# ATSAMR30E18A device description
Architecture: CORTEX-M0PLUS; Family: SAMR; Series: SAMR30
Registers are 32-bit, read-write, reset 0x0 unless marked. A register's access mark holds for its fields unless they carry their own. Offsets are from the block's base; [hi:lo] are bit positions; lines under a group give offsets from that group; {n}, {i} and the like mark numbered series; 'fields as' and 'values as' point back to an identical list; <NAME> marks a mode.

## PORT — Port Module
Instances: PORT 0x40002800, PORT_IOBUS 0x60000000
{0x0+0x80*i} GROUP[{i}] (i=0..2) group
  0x00 DIR — Data Direction
    [31:0] DIR — Port Data Direction
  0x04 DIRCLR (atomic clear of DIR) — Data Direction Clear
    [31:0] DIRCLR — Port Data Direction Clear
  0x08 DIRSET (atomic set of DIR) — Data Direction Set
    [31:0] DIRSET — Port Data Direction Set
  0x0C DIRTGL (atomic toggle of DIR) — Data Direction Toggle
    [31:0] DIRTGL — Port Data Direction Toggle
  0x10 OUT — Data Output Value
    [31:0] OUT — Port Data Output Value
  0x14 OUTCLR (atomic clear of OUT) — Data Output Value Clear
    [31:0] OUTCLR — Port Data Output Value Clear
  0x18 OUTSET (atomic set of OUT) — Data Output Value Set
    [31:0] OUTSET — Port Data Output Value Set
  0x1C OUTTGL (atomic toggle of OUT) — Data Output Value Toggle
    [31:0] OUTTGL — Port Data Output Value Toggle
  0x20 IN ro — Data Input Value
    [31:0] IN — Port Data Input Value
  0x24 CTRL — Control
    [31:0] SAMPLING — Input Sampling Mode
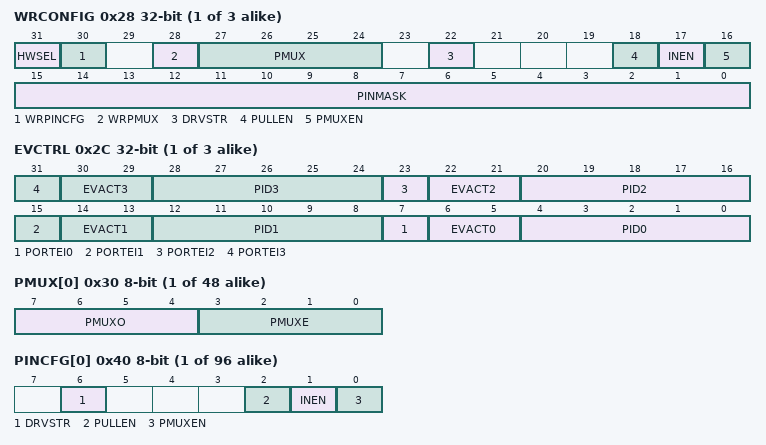
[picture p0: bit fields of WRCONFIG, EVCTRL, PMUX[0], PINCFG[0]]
  0x28 WRCONFIG wo — Write Configuration
    [31] HWSEL — Half-Word Select
    [30] WRPINCFG — Write PINCFG Registers
    [28] WRPMUX — Write PMUX Registers
    [27:24] PMUX — Peripheral Multiplexing Template
    [22] DRVSTR — Output Driver Strength Selection
    [18] PULLEN — Pull Enable
    [17] INEN — Input Enable
    [16] PMUXEN — Select Peripheral Multiplexer
    [15:0] PINMASK — Pin Mask for Multiple Pin Configuration
  0x2C EVCTRL — Event Input Control
    [8n+7] PORTEI{n} (n=0..3) — Port Event Enable Input {n}
    [8n+6:8n+5] EVACT{n} (n=0..3) — Port Event Action {n}
    [8n+4:8n] PID{n} (n=0..3) — Port Event Pin Identifier {n}
  {0x30+j} PMUX[{j}] (j=0..15) 8-bit — Peripheral Multiplexing n
    [7:4] PMUXO — Peripheral Multiplexing for Odd-Numbered Pin
    [3:0] PMUXE — Peripheral Multiplexing for Even-Numbered Pin
  {0x40+j} PINCFG[{j}] (j=0..31) 8-bit — Pin Configuration n
    [6] DRVSTR — Output Driver Strength Selection
    [2] PULLEN — Pull Enable
    [1] INEN — Input Enable
    [0] PMUXEN — Select Peripheral Multiplexer

## RFCTRL — RF212B control module
Instances: RFCTRL 0x42003C00
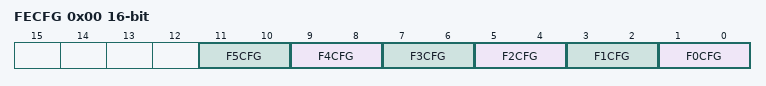
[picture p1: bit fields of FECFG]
0x00 FECFG 16-bit — Front-end control bus configuration
  [2n+1:2n] F{n}CFG (n=0..5) — Front-end control signal {n} configuration

## RSTC — Reset Controller
Instances: RSTC 0x40000800
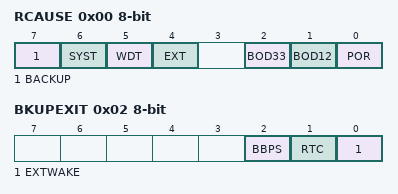
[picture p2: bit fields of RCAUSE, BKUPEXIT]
0x00 RCAUSE 8-bit ro reset not defined — Reset Cause
  [7] BACKUP — Backup Reset
  [6] SYST — System Reset Request
  [5] WDT — Watchdog Reset
  [4] EXT — External Reset
  [2] BOD33 — Brown Out 33 Detector Reset
  [1] BOD12 — Brown Out 12 Detector Reset
  [0] POR — Power On Reset
0x02 BKUPEXIT 8-bit ro reset not defined — Backup Exit Source
  [2] BBPS — Battery Backup Power Switch
  [1] RTC — Real Timer Counter Interrupt
  [0] EXTWAKE — External Wakeup
0x04 WKDBCONF 8-bit — Wakeup Debounce Configuration
  [4:0] WKDBCNT — Wakeup Debounce Counter
    0=OFF (No debouncing.Input pin is low or high level sensitive depending on its WKPOLx bit.); 1=2CK32 (Input pin shall be active for at least two 32kHz clock period.); 2=3CK32 (Input pin shall be active for at least three 32kHz clock period.); 3=32CK32 (Input pin shall be active for at least 32 32kHz clock period.); 4=512CK32 (Input pin shall be active for at least 512 32kHz clock period.); 5=4096CK32 (Input pin shall be active for at least 4096 32kHz clock period.); 6=32768CK32 (Input pin shall be active for at least 32768 32kHz clock period.)
0x08 WKPOL 16-bit — Wakeup Polarity
  [7:0] WKPOL
0x0C WKEN 16-bit — Wakeup Enable
  [7:0] WKEN
0x10 WKCAUSE 16-bit — Wakeup Cause

## USB_DESCRIPTOR — Universal Serial Bus
Modes: DEVICE when USB.CTRLA.MODE=0 (USB is Device); HOST when USB.CTRLA.MODE=1 (USB is Host)
{0x0+0x10*i} DEVICE_DESC_BANK[{i}] (i=0..1) <DEVICE> group
  0x00 ADDR <DEVICE> reset not defined — DEVICE_DESC_BANK Endpoint Bank, Adress of Data Buffer
    [31:0] ADDR — Adress of data buffer
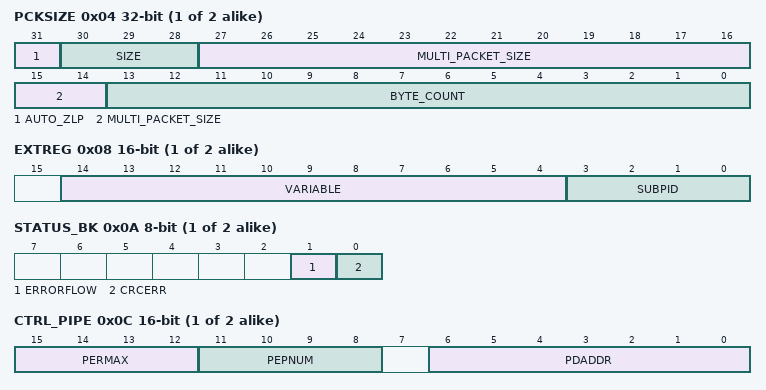
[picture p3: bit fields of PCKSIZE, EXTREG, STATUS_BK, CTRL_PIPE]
  0x04 PCKSIZE <DEVICE> reset not defined — DEVICE_DESC_BANK Endpoint Bank, Packet Size
    [31] AUTO_ZLP — Automatic Zero Length Packet
    [30:28] SIZE — Enpoint size
    [27:14] MULTI_PACKET_SIZE — Multi Packet In or Out size
    [13:0] BYTE_COUNT
  0x08 EXTREG <DEVICE> 16-bit reset not defined — DEVICE_DESC_BANK Endpoint Bank, Extended
    [14:4] VARIABLE — Variable field send with extended token
    [3:0] SUBPID — SUBPID field send with extended token
  0x0A STATUS_BK <DEVICE> 8-bit reset not defined — DEVICE_DESC_BANK Enpoint Bank, Status of Bank
    [1] ERRORFLOW — Error Flow Status
    [0] CRCERR — CRC Error Status
{0x0+0x10*i} HOST_DESC_BANK[{i}] (i=0..1) <HOST> group
  0x00 ADDR <HOST> reset not defined — HOST_DESC_BANK Host Bank, Adress of Data Buffer
    [31:0] ADDR — Adress of data buffer
  0x04 PCKSIZE <HOST> reset not defined — HOST_DESC_BANK Host Bank, Packet Size
    [31] AUTO_ZLP — Automatic Zero Length Packet
    [30:28] SIZE — Pipe size
    [27:14] MULTI_PACKET_SIZE — Multi Packet In or Out size
    [13:0] BYTE_COUNT
  0x08 EXTREG <HOST> 16-bit reset not defined — HOST_DESC_BANK Host Bank, Extended
    fields as DEVICE_DESC_BANK[0]<DEVICE>.EXTREG<DEVICE>
  0x0A STATUS_BK <HOST> 8-bit reset not defined — HOST_DESC_BANK Host Bank, Status of Bank
    [1] ERRORFLOW — Error Flow Status
    [0] CRCERR — CRC Error Status
  0x0C CTRL_PIPE <HOST> 16-bit — HOST_DESC_BANK Host Bank, Host Control Pipe
    [15:12] PERMAX — Pipe Error Max Number
    [11:8] PEPNUM — Pipe Endpoint Number
    [6:0] PDADDR — Pipe Device Adress
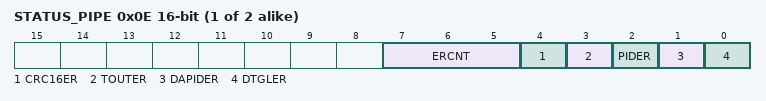
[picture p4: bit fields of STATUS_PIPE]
  0x0E STATUS_PIPE <HOST> 16-bit reset not defined — HOST_DESC_BANK Host Bank, Host Status Pipe
    [7:5] ERCNT — Pipe Error Count
    [4] CRC16ER — CRC16 Error
    [3] TOUTER — Time Out Error
    [2] PIDER — PID Error
    [1] DAPIDER — Data PID Error
    [0] DTGLER — Data Toggle Error

## Notices in the file
Copyright (c) 2018 Microchip Technology Inc.
SPDX-License-Identifier: Apache-2.0
Licensed under the Apache License, Version 2.0 (the "License");
you may not use this file except in compliance with the License.
You may obtain a copy of the License at
http://www.apache.org/licenses/LICENSE-2.0
Unless required by applicable law or agreed to in writing, software
distributed under the License is distributed on an "AS IS" BASIS,
WITHOUT WARRANTIES OR CONDITIONS OF ANY KIND, either express or implied.
See the License for the specific language governing permissions and
limitations under the License.
